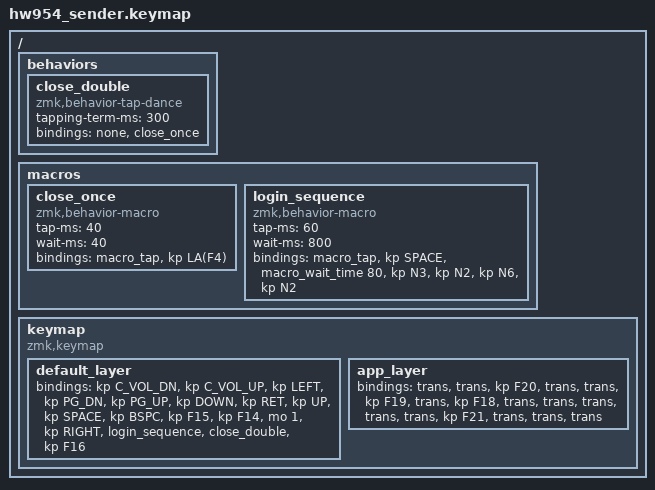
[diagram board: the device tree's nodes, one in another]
#include <behaviors.dtsi>
#include <dt-bindings/zmk/keys.h>

/ {
    behaviors {
        close_double: close_double {
            compatible = "zmk,behavior-tap-dance";
            #binding-cells = <0>;
            tapping-term-ms = <300>;
            bindings = <&none>, <&close_once>;
        };
    };
    macros {
        close_once: close_once {
            compatible = "zmk,behavior-macro";
            #binding-cells = <0>;
            tap-ms = <40>;
            wait-ms = <40>;
            bindings = <&macro_tap &kp LA(F4)>;
        };
        login_sequence: login_sequence {
            compatible = "zmk,behavior-macro";
            #binding-cells = <0>;
            tap-ms = <60>;
            // Wait after releasing SPACE so the Windows sign-in field can appear.
            wait-ms = <800>;
            bindings = <&macro_tap &kp SPACE>,
                       <&macro_wait_time 80>,
                       <&kp N3 &kp N2 &kp N6 &kp N2>;
        };
    };
    keymap {
        compatible = "zmk,keymap";
        default_layer {
            bindings = <
                &kp C_VOL_DN
                &kp C_VOL_UP
                &kp LEFT
                &kp PG_DN
                &kp PG_UP
                &kp DOWN
                &kp RET
                &kp UP
                &kp SPACE
                &kp BSPC
                &kp F15
                &kp F14
                &mo 1
                &kp RIGHT
                &login_sequence
                &close_double
                &kp F16
            >;
        };
        app_layer {
            bindings = <
                &trans
                &trans
                &kp F20
                &trans
                &trans
                &kp F19
                &trans
                &kp F18
                &trans
                &trans
                &trans
                &trans
                &trans
                &kp F21
                &trans
                &trans
                &trans
            >;
        };
    };
};
